# CY8C4245AXI_483 register map
File version: 0.1
PSoC 4200
Registers are 32-bit, read-write, no defined reset value unless marked. A register's access mark holds for its fields unless they carry their own. Offsets are from the block's base; lines under a group give offsets from that group; [hi:lo] are bit positions; {n}, {i} and the like mark numbered series; 'fields as' and 'values as' point back to an identical list; <NAME> marks a mode.

## Memory map
0x00000000 FECH
0x00000000 Speed
0x00000000 sensrotation
0x00000000 UART — Serial Communication Block
0x00000000 Stat_dir
0x00000000 PWM
0x00000000 QuadDec

## FECH
Base 0x00000000
0x40050108 COUNTER — Current counter value
0x4005010C CC — Compare / capture value
0x40050110 CC_BUF — Compare / capture buffer value
0x40050114 PERIOD — Period value
0x40050118 PERIOD_BUF — Period buffer value

## Speed
Base 0x00000000
0x40050148 COUNTER — Current counter value
0x4005014C CC — Compare / capture value
0x40050150 CC_BUF — Compare / capture buffer value
0x40050154 PERIOD — Period value
0x40050158 PERIOD_BUF — Period buffer value

## sensrotation
Base 0x00000000
0x400F0072 sensrotation_CONTROL_REG 8-bit

## Stat_dir
Base 0x00000000
0x400F0060 Stat_dir_STATUS_REG 8-bit
0x400F0080 Stat_dir_MASK_REG 8-bit
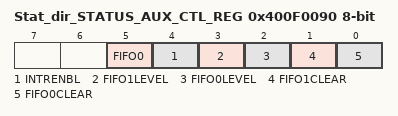
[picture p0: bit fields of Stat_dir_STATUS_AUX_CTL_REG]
0x400F0090 Stat_dir_STATUS_AUX_CTL_REG 8-bit
  [5] FIFO0 — FIFO0 clear
    1=ENABLED (Enable counter); 0=DISABLED (Disable counter)
  [4] INTRENBL — Enables or disables the Interrupt
    1=ENABLED (Interrupt enabled); 0=DISABLED (Interrupt disabled)
  [3] FIFO1LEVEL — FIFO level
    1=ENABLED (FIFO LVL: input mode: FIFO at least 1/2 empty; output mode: FIFO at least 1/2 full); 0=DISABLED (FIFO LVL: input mode: FIFO not full; output mode: FIFO not empty)
  [2] FIFO0LEVEL — FIFO level
    values as FIFO1LEVEL
  [1] FIFO1CLEAR — FIFO clear
    1=ENABLED (Clear FIFO state); 0=DISABLED (Normal FIFO operation)
  [0] FIFO0CLEAR — FIFO clear
    values as FIFO1CLEAR

## PWM
Base 0x00000000
0x40050188 COUNTER — Current counter value
0x4005018C CC — Compare / capture value
0x40050190 CC_BUF — Compare / capture buffer value
0x40050194 PERIOD — Period value
0x40050198 PERIOD_BUF — Period buffer value

## QuadDec
Base 0x00000000
0x400F0000 QuadDec_COUNTER 16-bit — UDB.A0 - Current Counter Value
0x400F0020 QuadDec_PERIOD 16-bit — UDB.D0 - Assigned Period
0x400F0030 QuadDec_COMPARE 16-bit — UDB.D1 - Assigned Compare Value
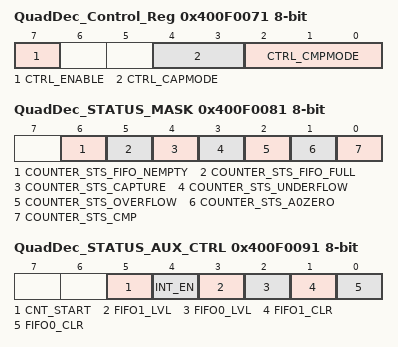
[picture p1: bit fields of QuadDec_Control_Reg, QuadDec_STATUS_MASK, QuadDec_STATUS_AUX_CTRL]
0x400F0071 QuadDec_Control_Reg 8-bit — UDB Control Register - Assigned Control Register Value
  [7] CTRL_ENABLE — Enable Counter
  [4:3] CTRL_CAPMODE — Capture mode
  [2:0] CTRL_CMPMODE — Compare mode
0x400F0081 QuadDec_STATUS_MASK 8-bit — UDB Status bits Interrupt Mask Enable Register
  [6] COUNTER_STS_FIFO_NEMPTY — FIFO Not Empty Status
  [5] COUNTER_STS_FIFO_FULL — FIFO Full Status
  [4] COUNTER_STS_CAPTURE — Capture Status
  [3] COUNTER_STS_UNDERFLOW — Underflow status
  [2] COUNTER_STS_OVERFLOW — Overflow status
  [1] COUNTER_STS_A0ZERO — A0 Zero ouput status
  [0] COUNTER_STS_CMP — Compare output status
0x400F0091 QuadDec_STATUS_AUX_CTRL 8-bit — UDB Auxilliary Control Register
  [5] CNT_START — FIFO0 clear
    0=E_CNT_START0 (Disable counter); 1=E_CNT_START1 (Enable counter)
  [4] INT_EN
    0=E_INT_EN0 (Interrupt disabled); 1=E_INT_EN1 (Interrupt enabled)
  [3] FIFO1_LVL — FIFO level
    0=E_FIFO_LVL_0 (FIFO LVL: input mode: FIFO not full; output mode: FIFO not empty); 1=E_FIFO_LVL_1 (FIFO LVL: input mode: FIFO at least 1/2 empty; output mode: FIFO at least 1/2 full)
  [2] FIFO0_LVL — FIFO level
    values as FIFO1_LVL
  [1] FIFO1_CLR — FIFO1 clear
    0=E_FIFO_CLR_0 (Normal FIFO operation); 1=E_FIFO_CLR_1 (Clear FIFO state)
  [0] FIFO0_CLR — FIFO0 clear
    values as FIFO1_CLR
